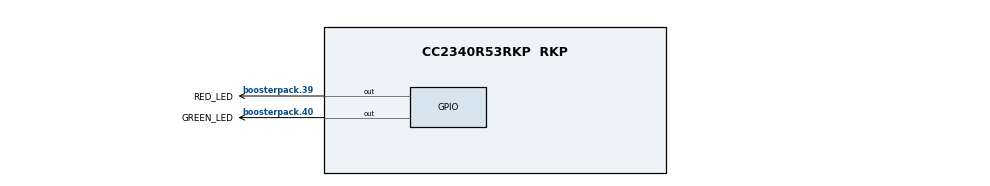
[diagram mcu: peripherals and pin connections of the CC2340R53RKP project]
/**
 *
 * @cliArgs --board "/ti/boards/LP_EM_CC2340R53" --device "CC2340R53RKP" --part "Default" --package "RKP" --rtos "freertos" --product "simplelink_lowpower_f3_sdk@9.20.00.81"
 * @versions {"tool":"1.28.0+4712"}
 */

/**
 * Import the modules used in this configuration.
 */
const FreeRTOS  = scripting.addModule("/freertos/FreeRTOS");
const exception = scripting.addModule("/freertos/exception");
const CCFG      = scripting.addModule("/ti/devices/CCFG");
const custom    = scripting.addModule("/ti/devices/radioconfig/custom");
//const Display   = scripting.addModule("/ti/display/Display");
//const Display1  = Display.addInstance();
const GPIO      = scripting.addModule("/ti/drivers/GPIO");
const GPIO1     = GPIO.addInstance();
const GPIO2     = GPIO.addInstance();
const Power     = scripting.addModule("/ti/drivers/Power");
const Settings  = scripting.addModule("/ti/posix/freertos/Settings");

/* ======== Board ======== */
var board = system.deviceData.board.name;

/**
 * Write custom configuration values to the imported modules.
 */
FreeRTOS.assertsEnabled = true;
FreeRTOS.idleStackSize  = 0x00000400;
FreeRTOS.timerStackSize = 0x00000400;

CCFG.writeEraseProt_ccfgSector = false;
CCFG.writeEraseProt_fcfgSector = false;
CCFG.writeEraseProt_engrSector = false;
CCFG.ccfgTemplate.$name        = "ti_devices_CCFG_CCFGCC23X0Template0";

//Display1.$hardware                = system.deviceData.board.components.XDS110UART;
//Display1.$name                    = "CONFIG_Display";
//Display1.uart.$name               = "CONFIG_Display_UART";
//Display1.uart.txPinInstance.$name = "CONFIG_PIN_UART_TX";

GPIO1.$name           = "RED_LED";
GPIO1.mode            = "Output";
GPIO1.gpioPin.$assign = "boosterpack.39";

GPIO2.$name           = "GREEN_LED";
GPIO2.mode            = "Output";
GPIO2.gpioPin.$assign = "boosterpack.40";

/**
 * Pinmux solution for unlocked pins/peripherals. This ensures that minor changes to the automatic solver in a future
 * version of the tool will not impact the pinmux you originally saw.  These lines can be completely deleted in order to
 * re-solve from scratch.
 */
//Display1.uart.uart.$suggestSolution              = "UART0";
//Display1.uart.uart.dmaTxChannel.$suggestSolution = "DMA_CH1";
//Display1.uart.uart.dmaRxChannel.$suggestSolution = "DMA_CH0";
//Display1.uart.uart.txPin.$suggestSolution        = "boosterpack.4";
